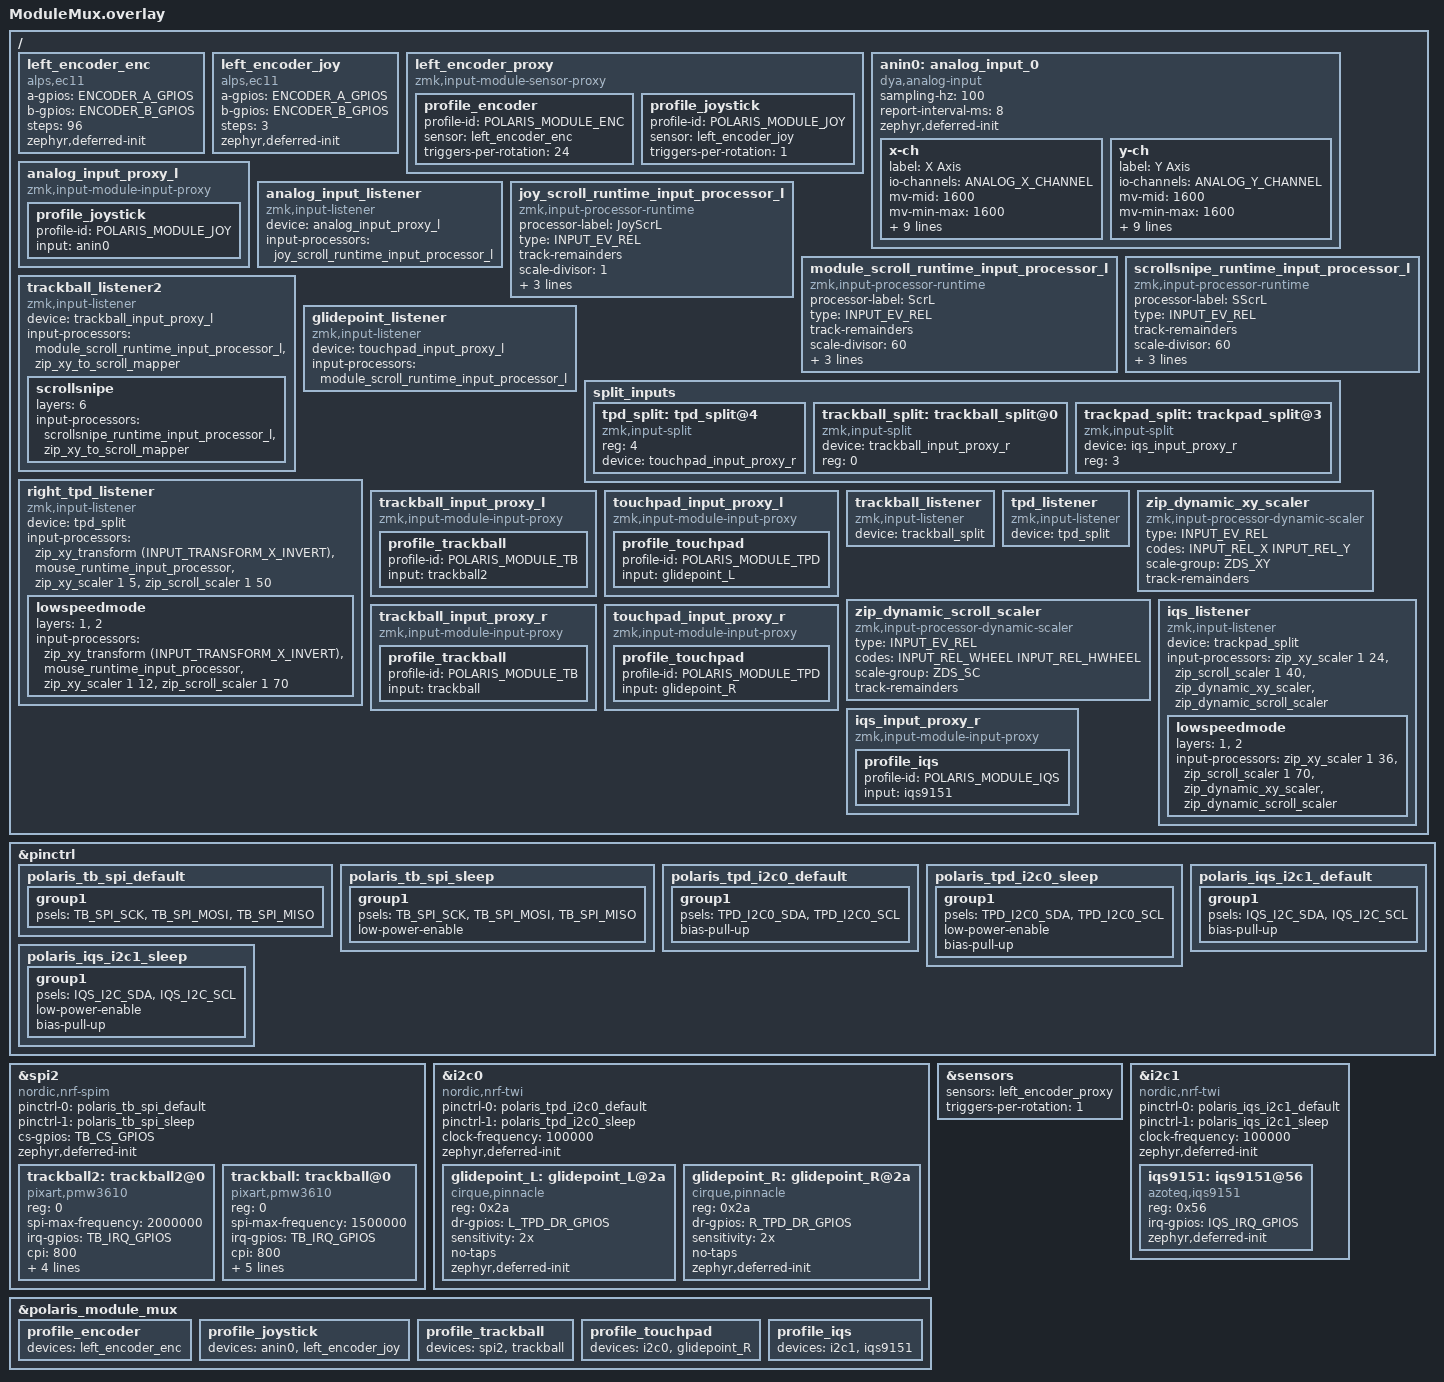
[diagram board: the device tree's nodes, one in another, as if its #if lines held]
#include <dt-bindings/polaris/module_select.h>
#include <dt-bindings/zmk/input_transform.h>
#include <dt-bindings/zmk/keys.h>
#include <dt-bindings/zmk/pointing.h>
#include <dt-bindings/zmk/zip_dynamic_scale.h>
#include <input/processors.dtsi>
#include <input/processors/runtime-input-processor.dtsi>
#include <zephyr/dt-bindings/input/input-event-codes.h>

&pinctrl {
	polaris_tb_spi_default: polaris_tb_spi_default {
		group1 {
			psels = <TB_SPI_SCK>,
				<TB_SPI_MOSI>,
				<TB_SPI_MISO>;
		};
	};

	polaris_tb_spi_sleep: polaris_tb_spi_sleep {
		group1 {
			psels = <TB_SPI_SCK>,
				<TB_SPI_MOSI>,
				<TB_SPI_MISO>;
			low-power-enable;
		};
	};

	polaris_tpd_i2c0_default: polaris_tpd_i2c0_default {
		group1 {
			psels = <TPD_I2C0_SDA>,
				<TPD_I2C0_SCL>;
			bias-pull-up;
		};
	};

	polaris_tpd_i2c0_sleep: polaris_tpd_i2c0_sleep {
		group1 {
			psels = <TPD_I2C0_SDA>,
				<TPD_I2C0_SCL>;
			low-power-enable;
			bias-pull-up;
		};
	};

	polaris_iqs_i2c1_default: polaris_iqs_i2c1_default {
		group1 {
			psels = <IQS_I2C_SDA>,
				<IQS_I2C_SCL>;
			bias-pull-up;
		};
	};

	polaris_iqs_i2c1_sleep: polaris_iqs_i2c1_sleep {
		group1 {
			psels = <IQS_I2C_SDA>,
				<IQS_I2C_SCL>;
			low-power-enable;
			bias-pull-up;
		};
	};
};

&spi2 {
	status = "okay";
	compatible = "nordic,nrf-spim";
	pinctrl-0 = <&polaris_tb_spi_default>;
	pinctrl-1 = <&polaris_tb_spi_sleep>;
	pinctrl-names = "default", "sleep";
	cs-gpios = TB_CS_GPIOS;
	zephyr,deferred-init;

#if defined(POLARIS_SPLIT_ROLE_CENTRAL)
	trackball2: trackball2@0 {
		status = "okay";
		compatible = "pixart,pmw3610";
		reg = <0>;
		spi-max-frequency = <2000000>;
		irq-gpios = TB_IRQ_GPIOS;
		cpi = <800>;
		evt-type = <INPUT_EV_REL>;
		x-input-code = <INPUT_REL_X>;
		y-input-code = <INPUT_REL_Y>;
		zephyr,deferred-init;
	};
#endif

#if defined(POLARIS_SPLIT_ROLE_PERIPHERAL)
	trackball: trackball@0 {
		status = "okay";
		compatible = "pixart,pmw3610";
		reg = <0>;
		spi-max-frequency = <1500000>;
		irq-gpios = TB_IRQ_GPIOS;
		cpi = <800>;
		evt-type = <INPUT_EV_REL>;
		x-input-code = <INPUT_REL_X>;
		y-input-code = <INPUT_REL_Y>;
		force-awake;
		zephyr,deferred-init;
	};
#endif
};

#if defined(POLARIS_SPLIT_ROLE_CENTRAL)
/ {
	left_encoder_enc: left_encoder_enc {
		compatible = "alps,ec11";
		a-gpios = ENCODER_A_GPIOS;
		b-gpios = ENCODER_B_GPIOS;
		steps = <96>;
		status = "okay";
		zephyr,deferred-init;
	};

	left_encoder_joy: left_encoder_joy {
		compatible = "alps,ec11";
		a-gpios = ENCODER_A_GPIOS;
		b-gpios = ENCODER_B_GPIOS;
		steps = <3>;
		status = "okay";
		zephyr,deferred-init;
	};

	left_encoder_proxy: left_encoder_proxy {
		compatible = "zmk,input-module-sensor-proxy";

		profile_encoder {
			profile-id = <POLARIS_MODULE_ENC>;
			sensor = <&left_encoder_enc>;
			triggers-per-rotation = <24>;
		};

		profile_joystick {
			profile-id = <POLARIS_MODULE_JOY>;
			sensor = <&left_encoder_joy>;
			triggers-per-rotation = <1>;
		};
	};

	anin0: analog_input_0 {
		compatible = "dya,analog-input";
		sampling-hz = <100>;
		report-interval-ms = <8>;
		zephyr,deferred-init;

		x-ch {
			label = "X Axis";
			io-channels = ANALOG_X_CHANNEL;
			mv-mid = <1600>;
			mv-min-max = <1600>;
			mv-deadzone = <88>;
			scale-multiplier = <1>;
			scale-divisor = <1>;
			output-min = <0>;
			output-max = <24>;
			invert;
			response-curve = <2>;
			evt-type = <INPUT_EV_REL>;
			input-code = <INPUT_REL_X>;
		};

		y-ch {
			label = "Y Axis";
			io-channels = ANALOG_Y_CHANNEL;
			mv-mid = <1600>;
			mv-min-max = <1600>;
			mv-deadzone = <88>;
			scale-multiplier = <1>;
			scale-divisor = <1>;
			output-min = <0>;
			output-max = <24>;
			invert;
			response-curve = <2>;
			evt-type = <INPUT_EV_REL>;
			input-code = <INPUT_REL_Y>;
		};
	};

	analog_input_proxy_l: analog_input_proxy_l {
		compatible = "zmk,input-module-input-proxy";

		profile_joystick {
			profile-id = <POLARIS_MODULE_JOY>;
			input = <&anin0>;
		};
	};

	analog_input_listener {
		status = "okay";
		compatible = "zmk,input-listener";
		device = <&analog_input_proxy_l>;
		input-processors = <&joy_scroll_runtime_input_processor_l>;
	};

	joy_scroll_runtime_input_processor_l: joy_scroll_runtime_input_processor_l {
		compatible = "zmk,input-processor-runtime";
		processor-label = "JoyScrL";
		type = <INPUT_EV_REL>;
		track-remainders;
		scale-divisor = <1>;
		#input-processor-cells = <0>;
	};

	module_scroll_runtime_input_processor_l: module_scroll_runtime_input_processor_l {
		compatible = "zmk,input-processor-runtime";
		processor-label = "ScrL";
		type = <INPUT_EV_REL>;
		track-remainders;
		scale-divisor = <60>;
		#input-processor-cells = <0>;
	};

	scrollsnipe_runtime_input_processor_l: scrollsnipe_runtime_input_processor_l {
		compatible = "zmk,input-processor-runtime";
		processor-label = "SScrL";
		type = <INPUT_EV_REL>;
		track-remainders;
		scale-divisor = <60>;
		#input-processor-cells = <0>;
	};

	trackball_listener2: trackball_listener2 {
		compatible = "zmk,input-listener";
		device = <&trackball_input_proxy_l>;
		status = "okay";
		input-processors = <&module_scroll_runtime_input_processor_l>,
				   <&zip_xy_to_scroll_mapper>;

		scrollsnipe {
			layers = <6>;
			input-processors = <&scrollsnipe_runtime_input_processor_l>,
					   <&zip_xy_to_scroll_mapper>;
		};
	};

	glidepoint_listener: glidepoint_listener {
		compatible = "zmk,input-listener";
		status = "okay";
		device = <&touchpad_input_proxy_l>;
		input-processors = <&module_scroll_runtime_input_processor_l>;
	};

	split_inputs {
		tpd_split: tpd_split@4 {
			compatible = "zmk,input-split";
			reg = <4>;
		};
	};

	right_tpd_listener: right_tpd_listener {
		compatible = "zmk,input-listener";
		status = "okay";
		device = <&tpd_split>;
		input-processors = <&zip_xy_transform (INPUT_TRANSFORM_X_INVERT)>,
				   <&mouse_runtime_input_processor>,
				   <&zip_xy_scaler 1 5>,
				   <&zip_scroll_scaler 1 50>;

		lowspeedmode {
			layers = <1>, <2>;
			input-processors = <&zip_xy_transform (INPUT_TRANSFORM_X_INVERT)>,
					   <&mouse_runtime_input_processor>,
					   <&zip_xy_scaler 1 12>,
					   <&zip_scroll_scaler 1 70>;
		};
	};
};

&joy_scroll_runtime_input_processor_l {
	x-codes = <INPUT_REL_X>;
	y-codes = <INPUT_REL_Y>;
	xy-to-scroll-enabled;
};

&module_scroll_runtime_input_processor_l {
	x-codes = <INPUT_REL_X>;
	y-codes = <INPUT_REL_Y>;
	xy-to-scroll-enabled;
};

&scrollsnipe_runtime_input_processor_l {
	x-codes = <INPUT_REL_X>;
	y-codes = <INPUT_REL_Y>;
	xy-to-scroll-enabled;
};

&i2c0 {
	status = "okay";
	compatible = "nordic,nrf-twi";
	pinctrl-0 = <&polaris_tpd_i2c0_default>;
	pinctrl-1 = <&polaris_tpd_i2c0_sleep>;
	pinctrl-names = "default", "sleep";
	clock-frequency = <100000>;
	#address-cells = <1>;
	#size-cells = <0>;
	zephyr,deferred-init;

	glidepoint_L: glidepoint_L@2a {
		compatible = "cirque,pinnacle";
		reg = <0x2a>;
		status = "okay";
		dr-gpios = L_TPD_DR_GPIOS;
		sensitivity = "2x";
		no-taps;
		zephyr,deferred-init;
	};
};

/ {
	trackball_input_proxy_l: trackball_input_proxy_l {
		compatible = "zmk,input-module-input-proxy";

		profile_trackball {
			profile-id = <POLARIS_MODULE_TB>;
			input = <&trackball2>;
		};
	};

	touchpad_input_proxy_l: touchpad_input_proxy_l {
		compatible = "zmk,input-module-input-proxy";

		profile_touchpad {
			profile-id = <POLARIS_MODULE_TPD>;
			input = <&glidepoint_L>;
		};
	};
};

&sensors {
	sensors = <&left_encoder_proxy>;
	triggers-per-rotation = <1>;
};

&polaris_module_mux {
	profile_encoder {
		devices = <&left_encoder_enc>;
	};

	profile_joystick {
		devices = <&anin0 &left_encoder_joy>;
	};

	profile_trackball {
		devices = <&spi2 &trackball2>;
	};

	profile_touchpad {
		devices = <&i2c0 &glidepoint_L>;
	};
};
#endif

#if defined(POLARIS_SPLIT_ROLE_PERIPHERAL)
/ {
	split_inputs {
		#address-cells = <1>;
		#size-cells = <0>;

		trackball_split: trackball_split@0 {
			compatible = "zmk,input-split";
			status = "okay";
			device = <&trackball_input_proxy_r>;
			reg = <0>;
		};

		trackpad_split: trackpad_split@3 {
			compatible = "zmk,input-split";
			status = "okay";
			device = <&iqs_input_proxy_r>;
			reg = <3>;
		};

		tpd_split: tpd_split@4 {
			compatible = "zmk,input-split";
			status = "okay";
			device = <&touchpad_input_proxy_r>;
			reg = <4>;
		};
	};

	trackball_listener: trackball_listener {
		compatible = "zmk,input-listener";
		status = "okay";
		device = <&trackball_split>;
	};

	tpd_listener: tpd_listener {
		compatible = "zmk,input-listener";
		status = "okay";
		device = <&tpd_split>;
	};

	zip_dynamic_xy_scaler: zip_dynamic_xy_scaler {
		compatible = "zmk,input-processor-dynamic-scaler";
		#input-processor-cells = <0>;
		type = <INPUT_EV_REL>;
		codes = <INPUT_REL_X INPUT_REL_Y>;
		scale-group = <ZDS_XY>;
		track-remainders;
	};

	zip_dynamic_scroll_scaler: zip_dynamic_scroll_scaler {
		compatible = "zmk,input-processor-dynamic-scaler";
		#input-processor-cells = <0>;
		type = <INPUT_EV_REL>;
		codes = <INPUT_REL_WHEEL INPUT_REL_HWHEEL>;
		scale-group = <ZDS_SC>;
		track-remainders;
	};

	iqs_listener: iqs_listener {
		compatible = "zmk,input-listener";
		status = "okay";
		device = <&trackpad_split>;
		input-processors = <&zip_xy_scaler 1 24>,
				   <&zip_scroll_scaler 1 40>,
				   <&zip_dynamic_xy_scaler>,
				   <&zip_dynamic_scroll_scaler>;

		lowspeedmode {
			layers = <1>, <2>;
			input-processors = <&zip_xy_scaler 1 36>,
					   <&zip_scroll_scaler 1 70>,
					   <&zip_dynamic_xy_scaler>,
					   <&zip_dynamic_scroll_scaler>;
		};
	};
};

&i2c0 {
	status = "okay";
	compatible = "nordic,nrf-twi";
	pinctrl-0 = <&polaris_tpd_i2c0_default>;
	pinctrl-1 = <&polaris_tpd_i2c0_sleep>;
	pinctrl-names = "default", "sleep";
	clock-frequency = <100000>;
	#address-cells = <1>;
	#size-cells = <0>;
	zephyr,deferred-init;

	glidepoint_R: glidepoint_R@2a {
		compatible = "cirque,pinnacle";
		reg = <0x2a>;
		status = "okay";
		dr-gpios = R_TPD_DR_GPIOS;
		sensitivity = "2x";
		no-taps;
		zephyr,deferred-init;
	};
};

&i2c1 {
	status = "okay";
	compatible = "nordic,nrf-twi";
	pinctrl-0 = <&polaris_iqs_i2c1_default>;
	pinctrl-1 = <&polaris_iqs_i2c1_sleep>;
	pinctrl-names = "default", "sleep";
	clock-frequency = <100000>;
	#address-cells = <1>;
	#size-cells = <0>;
	zephyr,deferred-init;

	iqs9151: iqs9151@56 {
		compatible = "azoteq,iqs9151";
		reg = <0x56>;
		status = "okay";
		irq-gpios = IQS_IRQ_GPIOS;
		zephyr,deferred-init;
	};
};

/ {
	trackball_input_proxy_r: trackball_input_proxy_r {
		compatible = "zmk,input-module-input-proxy";

		profile_trackball {
			profile-id = <POLARIS_MODULE_TB>;
			input = <&trackball>;
		};
	};

	touchpad_input_proxy_r: touchpad_input_proxy_r {
		compatible = "zmk,input-module-input-proxy";

		profile_touchpad {
			profile-id = <POLARIS_MODULE_TPD>;
			input = <&glidepoint_R>;
		};
	};

	iqs_input_proxy_r: iqs_input_proxy_r {
		compatible = "zmk,input-module-input-proxy";

		profile_iqs {
			profile-id = <POLARIS_MODULE_IQS>;
			input = <&iqs9151>;
		};
	};
};

&polaris_module_mux {
	profile_trackball {
		devices = <&spi2 &trackball>;
	};

	profile_touchpad {
		devices = <&i2c0 &glidepoint_R>;
	};

	profile_iqs {
		devices = <&i2c1 &iqs9151>;
	};
};
#endif
